# PIC32MZ1064DAL176 register map
Vendor: Microchip
Registers are 32-bit, read-write, reset 0x0 unless marked. A register's access mark holds for its fields unless they carry their own. Addresses are absolute, and some are shared; only a register's first bit layout is shown; [hi:lo] are bit positions; {n}, {i} and the like mark numbered series.

## PORTC
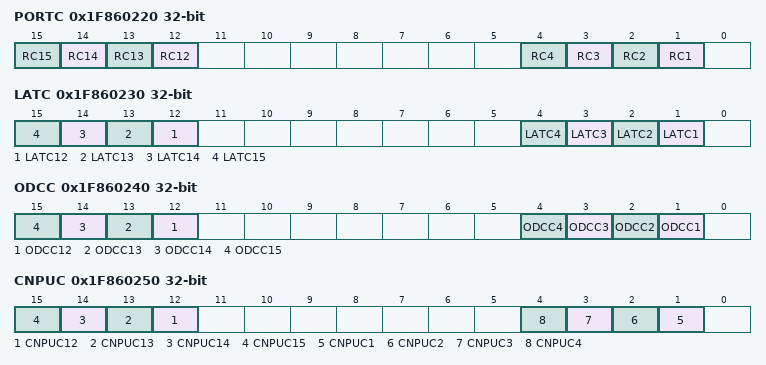
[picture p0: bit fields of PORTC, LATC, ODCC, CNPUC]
0x1F860220 PORTC reset not defined — (power-on value ----------------xxxx-------xxxx-)
  [n] RC{n} (n=12..15), [n] RC{n} (n=1..4)
0x1F860230 LATC reset not defined — (power-on value ----------------xxxx-------xxxx-)
  [n] LATC{n} (n=12..15), [n] LATC{n} (n=1..4)
0x1F860240 ODCC
  [n] ODCC{n} (n=12..15), [n] ODCC{n} (n=1..4)
0x1F860250 CNPUC
  [n] CNPUC{n} (n=12..15), [n] CNPUC{n} (n=1..4)
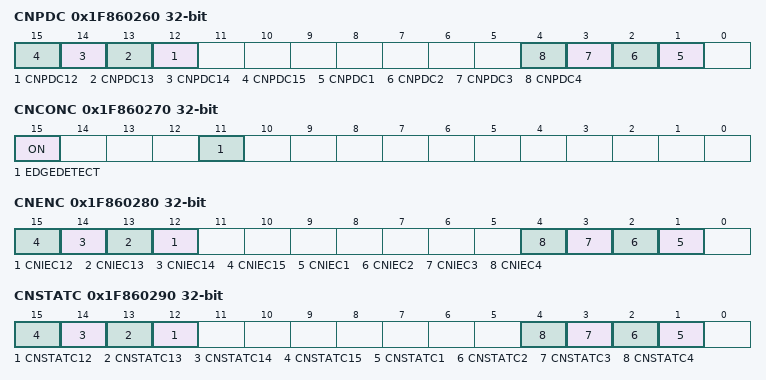
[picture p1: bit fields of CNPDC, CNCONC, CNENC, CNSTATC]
0x1F860260 CNPDC
  [n] CNPDC{n} (n=12..15), [n] CNPDC{n} (n=1..4)
0x1F860270 CNCONC
  [15] ON, [11] EDGEDETECT
0x1F860280 CNENC
  [n] CNIEC{n} (n=12..15), [n] CNIEC{n} (n=1..4)
0x1F860290 CNSTATC
  [n] CNSTATC{n} (n=12..15), [n] CNSTATC{n} (n=1..4)
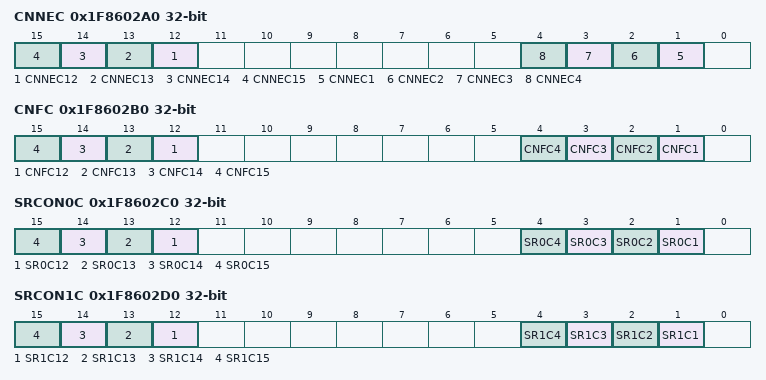
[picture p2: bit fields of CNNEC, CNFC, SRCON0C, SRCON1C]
0x1F8602A0 CNNEC
  [n] CNNEC{n} (n=12..15), [n] CNNEC{n} (n=1..4)
0x1F8602B0 CNFC
  [n] CNFC{n} (n=12..15), [n] CNFC{n} (n=1..4)
0x1F8602C0 SRCON0C
  [n] SR0C{n} (n=12..15), [n] SR0C{n} (n=1..4)
0x1F8602D0 SRCON1C
  [n] SR1C{n} (n=12..15), [n] SR1C{n} (n=1..4)

## PORTD
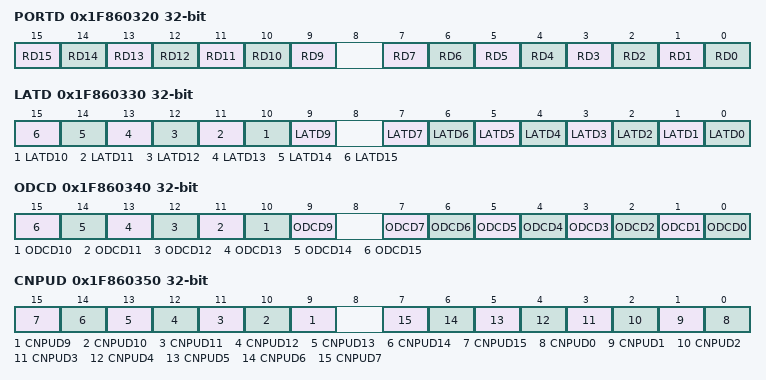
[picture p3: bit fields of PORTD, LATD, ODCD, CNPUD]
0x1F860320 PORTD reset not defined — (power-on value ----------------xxxxxxx-xxxxxxxx)
  [n] RD{n} (n=9..15), [n] RD{n} (n=0..7)
0x1F860330 LATD reset not defined — (power-on value ----------------xxxxxxx-xxxxxxxx)
  [n] LATD{n} (n=9..15), [n] LATD{n} (n=0..7)
0x1F860340 ODCD
  [n] ODCD{n} (n=9..15), [n] ODCD{n} (n=0..7)
0x1F860350 CNPUD
  [n] CNPUD{n} (n=9..15), [n] CNPUD{n} (n=0..7)
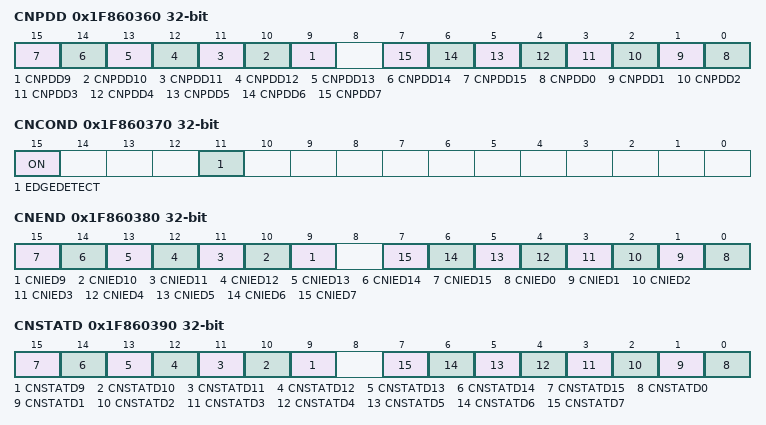
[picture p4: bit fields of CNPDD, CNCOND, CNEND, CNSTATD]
0x1F860360 CNPDD
  [n] CNPDD{n} (n=9..15), [n] CNPDD{n} (n=0..7)
0x1F860370 CNCOND
  [15] ON, [11] EDGEDETECT
0x1F860380 CNEND
  [n] CNIED{n} (n=9..15), [n] CNIED{n} (n=0..7)
0x1F860390 CNSTATD
  [n] CNSTATD{n} (n=9..15), [n] CNSTATD{n} (n=0..7)
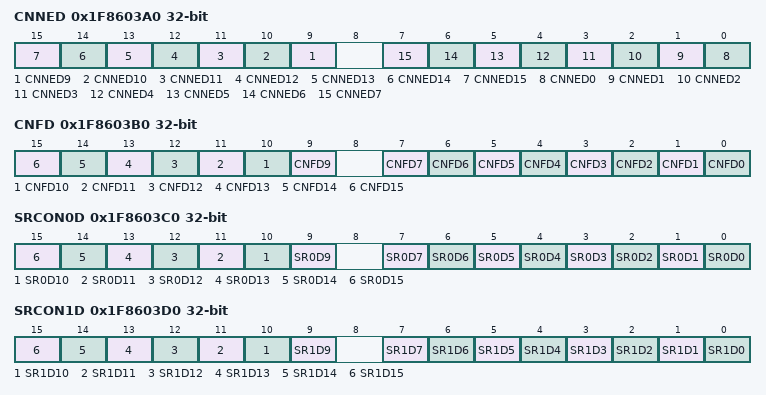
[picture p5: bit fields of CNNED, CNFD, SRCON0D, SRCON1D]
0x1F8603A0 CNNED
  [n] CNNED{n} (n=9..15), [n] CNNED{n} (n=0..7)
0x1F8603B0 CNFD
  [n] CNFD{n} (n=9..15), [n] CNFD{n} (n=0..7)
0x1F8603C0 SRCON0D
  [n] SR0D{n} (n=9..15), [n] SR0D{n} (n=0..7)
0x1F8603D0 SRCON1D
  [n] SR1D{n} (n=9..15), [n] SR1D{n} (n=0..7)

## PORTE
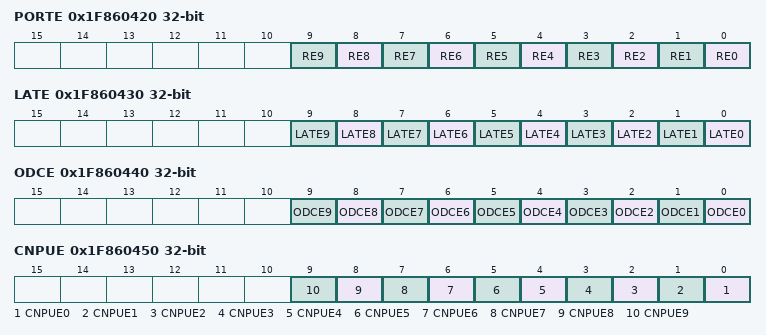
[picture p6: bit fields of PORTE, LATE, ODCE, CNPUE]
0x1F860420 PORTE reset not defined — (power-on value ----------------------xxxxxxxxxx)
  [n] RE{n} (n=0..9)
0x1F860430 LATE reset not defined — (power-on value ----------------------xxxxxxxxxx)
  [n] LATE{n} (n=0..9)
0x1F860440 ODCE
  [n] ODCE{n} (n=0..9)
0x1F860450 CNPUE
  [n] CNPUE{n} (n=0..9)
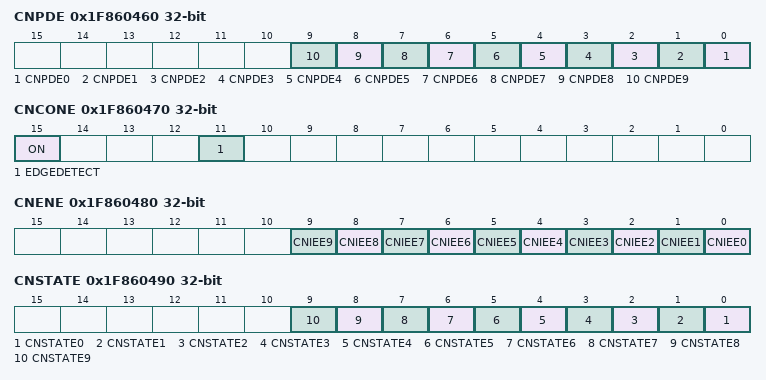
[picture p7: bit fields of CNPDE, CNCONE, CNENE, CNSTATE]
0x1F860460 CNPDE
  [n] CNPDE{n} (n=0..9)
0x1F860470 CNCONE
  [15] ON, [11] EDGEDETECT
0x1F860480 CNENE
  [n] CNIEE{n} (n=0..9)
0x1F860490 CNSTATE
  [n] CNSTATE{n} (n=0..9)
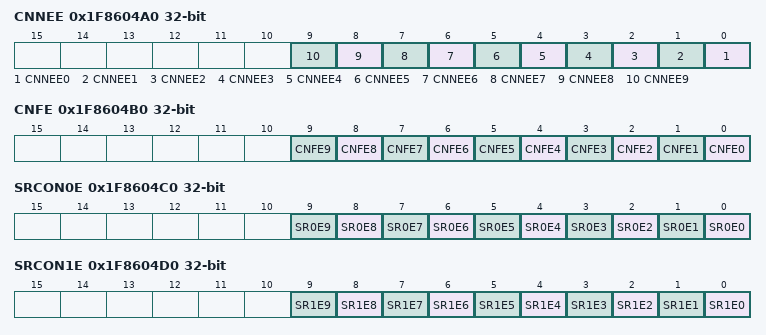
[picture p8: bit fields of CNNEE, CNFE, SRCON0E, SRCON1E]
0x1F8604A0 CNNEE
  [n] CNNEE{n} (n=0..9)
0x1F8604B0 CNFE
  [n] CNFE{n} (n=0..9)
0x1F8604C0 SRCON0E
  [n] SR0E{n} (n=0..9)
0x1F8604D0 SRCON1E
  [n] SR1E{n} (n=0..9)

## PORTF
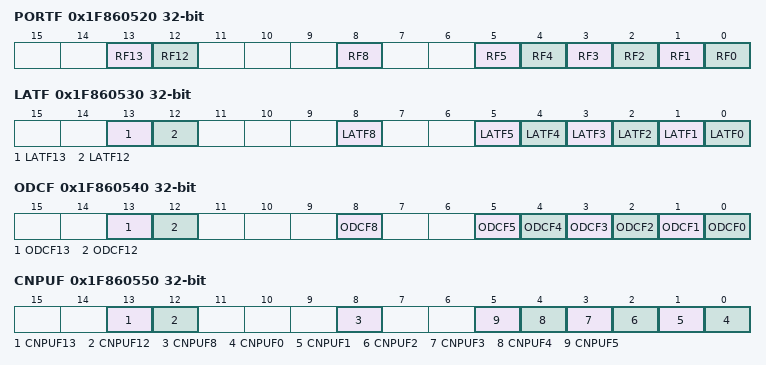
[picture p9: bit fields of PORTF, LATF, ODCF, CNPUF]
0x1F860520 PORTF reset not defined — (power-on value ------------------xx---x--xxxxxx)
  [13] RF13, [12] RF12, [8] RF8, [n] RF{n} (n=0..5)
0x1F860530 LATF reset not defined — (power-on value ------------------xx---x--xxxxxx)
  [13] LATF13, [12] LATF12, [8] LATF8, [n] LATF{n} (n=0..5)
0x1F860540 ODCF
  [13] ODCF13, [12] ODCF12, [8] ODCF8, [n] ODCF{n} (n=0..5)
0x1F860550 CNPUF
  [13] CNPUF13, [12] CNPUF12, [8] CNPUF8, [n] CNPUF{n} (n=0..5)
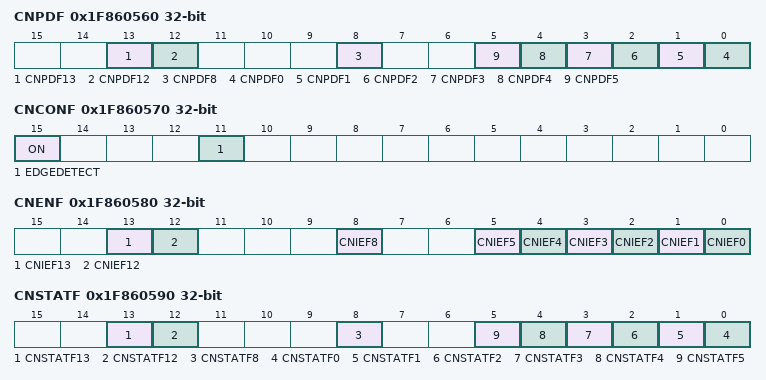
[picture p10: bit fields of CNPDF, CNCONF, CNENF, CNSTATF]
0x1F860560 CNPDF
  [13] CNPDF13, [12] CNPDF12, [8] CNPDF8, [n] CNPDF{n} (n=0..5)
0x1F860570 CNCONF
  [15] ON, [11] EDGEDETECT
0x1F860580 CNENF
  [13] CNIEF13, [12] CNIEF12, [8] CNIEF8, [n] CNIEF{n} (n=0..5)
0x1F860590 CNSTATF
  [13] CNSTATF13, [12] CNSTATF12, [8] CNSTATF8, [n] CNSTATF{n} (n=0..5)
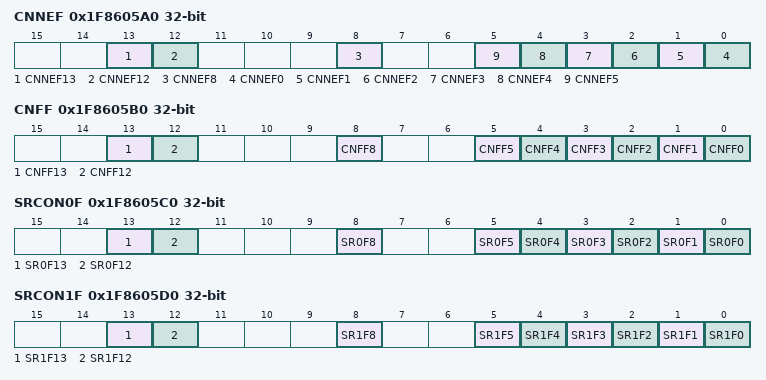
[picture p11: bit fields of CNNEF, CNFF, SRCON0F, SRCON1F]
0x1F8605A0 CNNEF
  [13] CNNEF13, [12] CNNEF12, [8] CNNEF8, [n] CNNEF{n} (n=0..5)
0x1F8605B0 CNFF
  [13] CNFF13, [12] CNFF12, [8] CNFF8, [n] CNFF{n} (n=0..5)
0x1F8605C0 SRCON0F
  [13] SR0F13, [12] SR0F12, [8] SR0F8, [n] SR0F{n} (n=0..5)
0x1F8605D0 SRCON1F
  [13] SR1F13, [12] SR1F12, [8] SR1F8, [n] SR1F{n} (n=0..5)

## PORTG
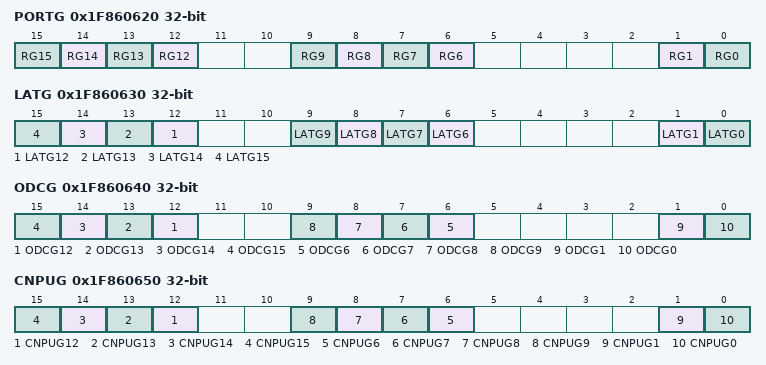
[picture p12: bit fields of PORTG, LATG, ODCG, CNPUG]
0x1F860620 PORTG reset not defined — (power-on value ----------------xxxx--xxxx----xx)
  [n] RG{n} (n=12..15), [n] RG{n} (n=6..9), [1] RG1, [0] RG0
0x1F860630 LATG reset not defined — (power-on value ----------------xxxx--xxxx----xx)
  [n] LATG{n} (n=12..15), [n] LATG{n} (n=6..9), [1] LATG1, [0] LATG0
0x1F860640 ODCG
  [n] ODCG{n} (n=12..15), [n] ODCG{n} (n=6..9), [1] ODCG1, [0] ODCG0
0x1F860650 CNPUG
  [n] CNPUG{n} (n=12..15), [n] CNPUG{n} (n=6..9), [1] CNPUG1, [0] CNPUG0
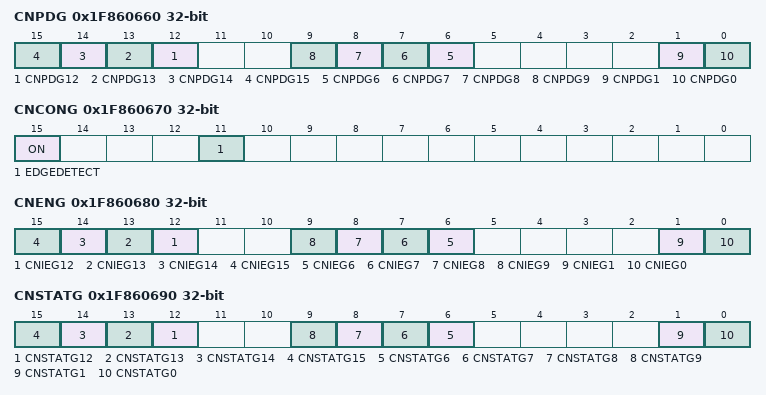
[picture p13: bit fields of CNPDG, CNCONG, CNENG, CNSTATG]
0x1F860660 CNPDG
  [n] CNPDG{n} (n=12..15), [n] CNPDG{n} (n=6..9), [1] CNPDG1, [0] CNPDG0
0x1F860670 CNCONG
  [15] ON, [11] EDGEDETECT
0x1F860680 CNENG
  [n] CNIEG{n} (n=12..15), [n] CNIEG{n} (n=6..9), [1] CNIEG1, [0] CNIEG0
0x1F860690 CNSTATG
  [n] CNSTATG{n} (n=12..15), [n] CNSTATG{n} (n=6..9), [1] CNSTATG1, [0] CNSTATG0
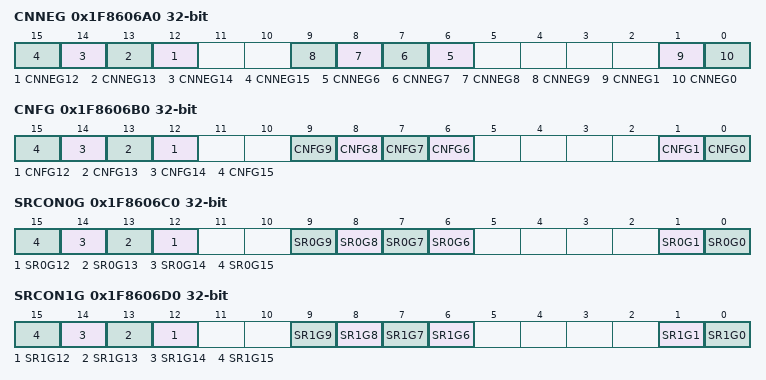
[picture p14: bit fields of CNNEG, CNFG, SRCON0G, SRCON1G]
0x1F8606A0 CNNEG
  [n] CNNEG{n} (n=12..15), [n] CNNEG{n} (n=6..9), [1] CNNEG1, [0] CNNEG0
0x1F8606B0 CNFG
  [n] CNFG{n} (n=12..15), [n] CNFG{n} (n=6..9), [1] CNFG1, [0] CNFG0
0x1F8606C0 SRCON0G
  [n] SR0G{n} (n=12..15), [n] SR0G{n} (n=6..9), [1] SR0G1, [0] SR0G0
0x1F8606D0 SRCON1G
  [n] SR1G{n} (n=12..15), [n] SR1G{n} (n=6..9), [1] SR1G1, [0] SR1G0
